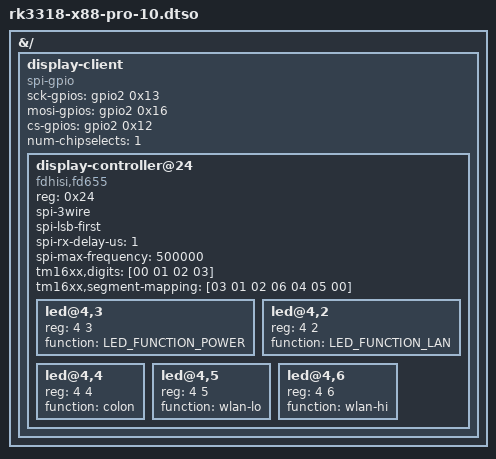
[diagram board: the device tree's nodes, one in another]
/dts-v1/;
/plugin/;

#include <dt-bindings/gpio/gpio.h>
#include <dt-bindings/leds/common.h>

&{/} {

	display-client {
		#address-cells = <1>;
		#size-cells = <0>;
		compatible = "spi-gpio";
		sck-gpios = <&gpio2 0x13 0>;
		mosi-gpios = <&gpio2 0x16 0>;
		cs-gpios = <&gpio2 0x12 0>;
		num-chipselects = <1>;

		display-controller@24 {
			compatible = "fdhisi,fd655";
			reg = <0x24>;
			spi-3wire;
			spi-lsb-first;
			spi-rx-delay-us = <1>;
			spi-max-frequency = <500000>;

			tm16xx,digits = [00 01 02 03];
                        tm16xx,segment-mapping = [03 01 02 06 04 05 00];

			#address-cells = <2>;
			#size-cells = <0>;
			
			led@4,3 {
				reg = <4 3>;
				function = LED_FUNCTION_POWER;
			};
			
			led@4,2 {
				reg = <4 2>;
				function = LED_FUNCTION_LAN;
			};
			
			led@4,4 {
				reg = <4 4>;
				function = "colon";
			};
			
			led@4,5 {
				reg = <4 5>;
				function = "wlan-lo";
			};
			
			led@4,6 {
				reg = <4 6>;
				function = "wlan-hi";
			};

		};
	};
};

